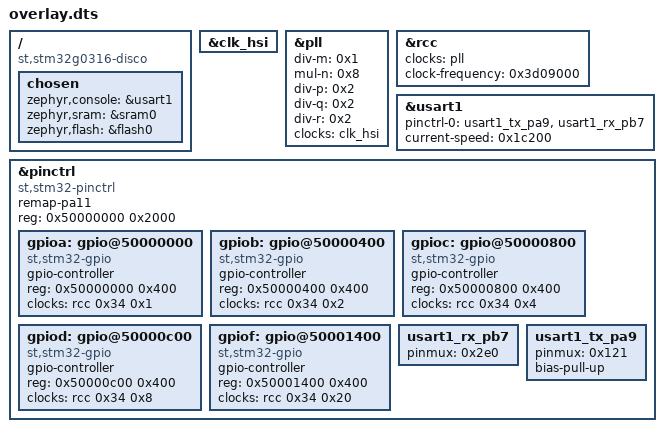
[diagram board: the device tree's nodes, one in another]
/ {
	compatible = "st,stm32g0316-disco";
	chosen {
		zephyr,console = &usart1;
		zephyr,sram = &sram0;
		zephyr,flash = &flash0;
	};
};
&clk_hsi{
	status = "okay";
};
&pll{
	status = "okay";
	div-m = < 0x1 >;
	mul-n = < 0x8 >;
	div-p = < 0x2 >;
	div-q = < 0x2 >;
	div-r = < 0x2 >;
	clocks = < &clk_hsi >;
};
&rcc{
	clocks = < &pll >;
	clock-frequency = < 0x3d09000 >;
};
&usart1{
	status = "okay";
	pinctrl-0 = < &usart1_tx_pa9 &usart1_rx_pb7 >;
	pinctrl-names = "default";
	current-speed = < 0x1c200 >;
};
&pinctrl{
	remap-pa11;
};
&pinctrl{
	compatible = "st,stm32-pinctrl";
	#address-cells = < 0x1 >;
	#size-cells = < 0x1 >;
	reg = < 0x50000000 0x2000 >;
	remap-pa11;
	gpioa: gpio@50000000 {
		compatible = "st,stm32-gpio";
		gpio-controller;
		#gpio-cells = < 0x2 >;
		reg = < 0x50000000 0x400 >;
		clocks = < &rcc 0x34 0x1 >;
	};
	gpiob: gpio@50000400 {
		compatible = "st,stm32-gpio";
		gpio-controller;
		#gpio-cells = < 0x2 >;
		reg = < 0x50000400 0x400 >;
		clocks = < &rcc 0x34 0x2 >;
	};
	gpioc: gpio@50000800 {
		compatible = "st,stm32-gpio";
		gpio-controller;
		#gpio-cells = < 0x2 >;
		reg = < 0x50000800 0x400 >;
		clocks = < &rcc 0x34 0x4 >;
	};
	gpiod: gpio@50000c00 {
		compatible = "st,stm32-gpio";
		gpio-controller;
		#gpio-cells = < 0x2 >;
		reg = < 0x50000c00 0x400 >;
		clocks = < &rcc 0x34 0x8 >;
	};
	gpiof: gpio@50001400 {
		compatible = "st,stm32-gpio";
		gpio-controller;
		#gpio-cells = < 0x2 >;
		reg = < 0x50001400 0x400 >;
		clocks = < &rcc 0x34 0x20 >;
	};
	usart1_rx_pb7: usart1_rx_pb7 {
		pinmux = < 0x2e0 >;
	};
	usart1_tx_pa9: usart1_tx_pa9 {
		pinmux = < 0x121 >;
		bias-pull-up;
	};
};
